# GD32A72_A74x register map
File version: 1.0
CPU: CM7 r2p1, little endian, MPU, FPU, DSP, 4 interrupt priority bits
Registers are 32-bit, read-write, reset 0x0 unless marked. A register's access mark holds for its fields unless they carry their own. Offsets are from the block's base; [hi:lo] are bit positions; {n}, {i} and the like mark numbered series; 'fields as' and 'values as' point back to an identical list.

## TRIGSEL — Trigger selection controller
Base 0x40012000
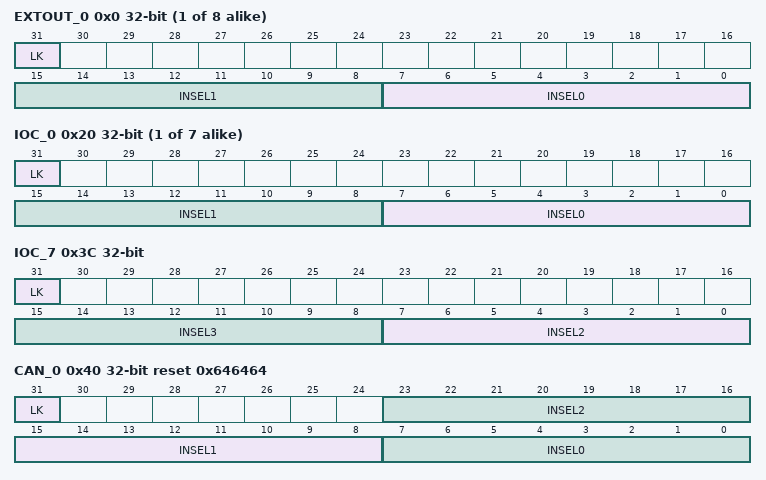
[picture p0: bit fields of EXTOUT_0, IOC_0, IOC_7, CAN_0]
{0x0+4i} EXTOUT_{i} (i=0..7) — Trigger selection for EXTOUT register {i}
  [31] LK — TRIGSEL register lock
  [15:8] INSEL1 — Trigger input source selection for output1
  [7:0] INSEL0 — Trigger input source selection for output0
{0x20+4i} IOC_{i} (i=0..6) — Trigger selection for IOC register {i}
  fields as EXTOUT_0
0x3C IOC_7 — Trigger selection for IOC register 7
  [31] LK — TRIGSEL register lock
  [15:8] INSEL3 — Trigger input source selection for output1
  [7:0] INSEL2 — Trigger input source selection for output0
0x40 CAN_0 reset 0x646464 — Trigger selection for CAN register 0
  [31] LK — TRIGSEL register lock
  [23:16] INSEL2 — Trigger input source selection for output2
  [15:8] INSEL1 — Trigger input source selection for output1
  [7:0] INSEL0 — Trigger input source selection for output0
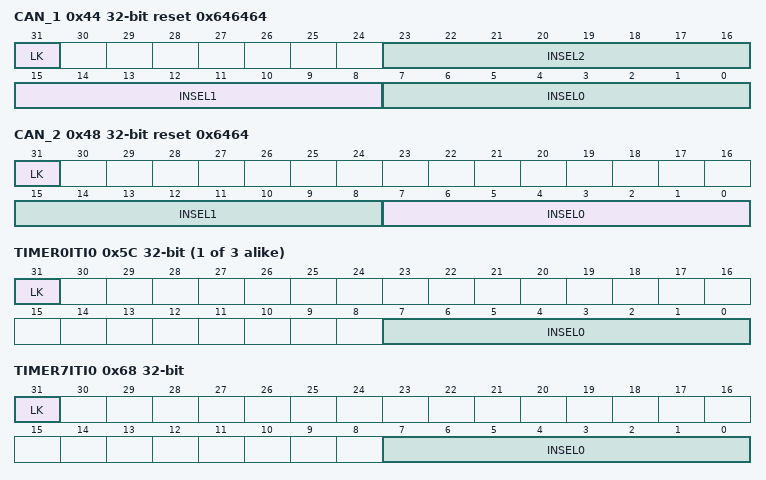
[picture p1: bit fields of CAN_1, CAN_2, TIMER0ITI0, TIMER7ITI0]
0x44 CAN_1 reset 0x646464 — Trigger selection for CAN register 1
  fields as CAN_0
0x48 CAN_2 reset 0x6464 — Trigger selection for CAN register 2
  fields as EXTOUT_0
{0x5C+4i} TIMER{i}ITI0 (i=0..2) — Trigger selection for TIMER{i}_ITI0 register
  [31] LK — TRIGSEL register lock
  [7:0] INSEL0 — Trigger input source selection for output0
0x68 TIMER7ITI0 — Trigger selection for TIMER7_ITI0 register
  fields as TIMER0ITI0
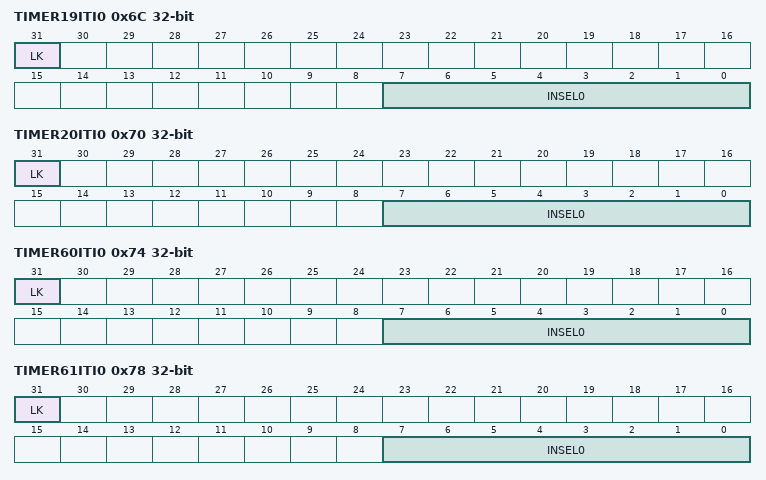
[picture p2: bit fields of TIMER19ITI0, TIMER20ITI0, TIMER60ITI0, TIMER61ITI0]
0x6C TIMER19ITI0 — Trigger selection for TIMER19_ITI0 register
  fields as TIMER0ITI0
0x70 TIMER20ITI0 — Trigger selection for TIMER20_ITI0 register
  fields as TIMER0ITI0
0x74 TIMER60ITI0 — Trigger selection for TIMER60_ITI0 register
  fields as TIMER0ITI0
0x78 TIMER61ITI0 — Trigger selection for TIMER61_ITI0 register
  fields as TIMER0ITI0
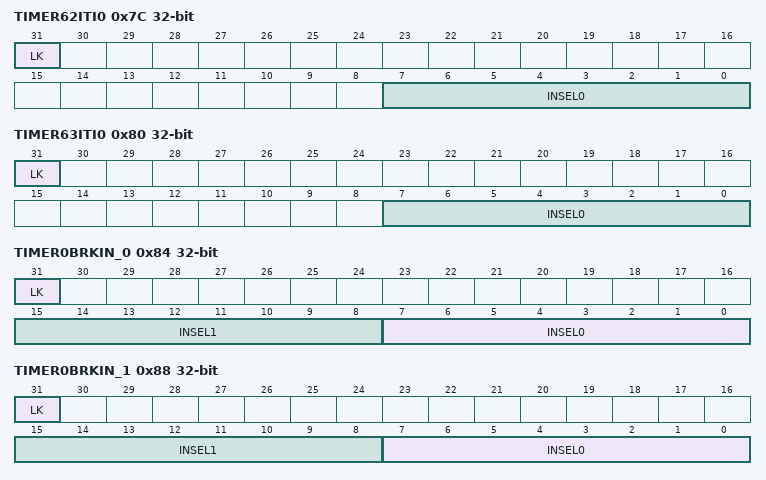
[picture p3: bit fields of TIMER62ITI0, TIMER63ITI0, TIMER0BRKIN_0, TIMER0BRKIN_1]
0x7C TIMER62ITI0 — Trigger selection for TIMER62_ITI0 register
  fields as TIMER0ITI0
0x80 TIMER63ITI0 — Trigger selection for TIMER63_ITI0 register
  fields as TIMER0ITI0
0x84 TIMER0BRKIN_0 — Trigger selection for TIMER0_BRKIN register 0
  fields as EXTOUT_0
0x88 TIMER0BRKIN_1 — Trigger selection for TIMER0_BRKIN register 1
  fields as EXTOUT_0
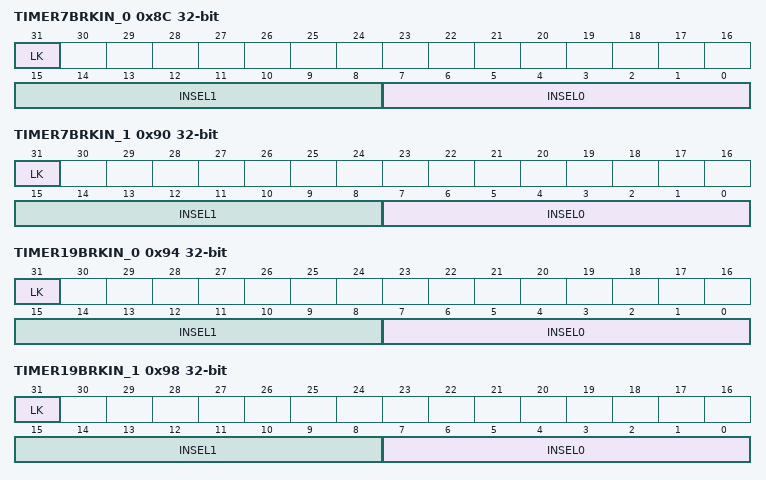
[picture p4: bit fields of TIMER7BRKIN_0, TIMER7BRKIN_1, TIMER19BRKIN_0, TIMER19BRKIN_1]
0x8C TIMER7BRKIN_0 — Trigger selection for TIMER7_BRKIN register 0
  fields as EXTOUT_0
0x90 TIMER7BRKIN_1 — Trigger selection for TIMER7_BRKIN register 1
  fields as EXTOUT_0
0x94 TIMER19BRKIN_0 — Trigger selection for TIMER19_BRKIN register 0
  fields as EXTOUT_0
0x98 TIMER19BRKIN_1 — Trigger selection for TIMER19_BRKIN register 1
  fields as EXTOUT_0
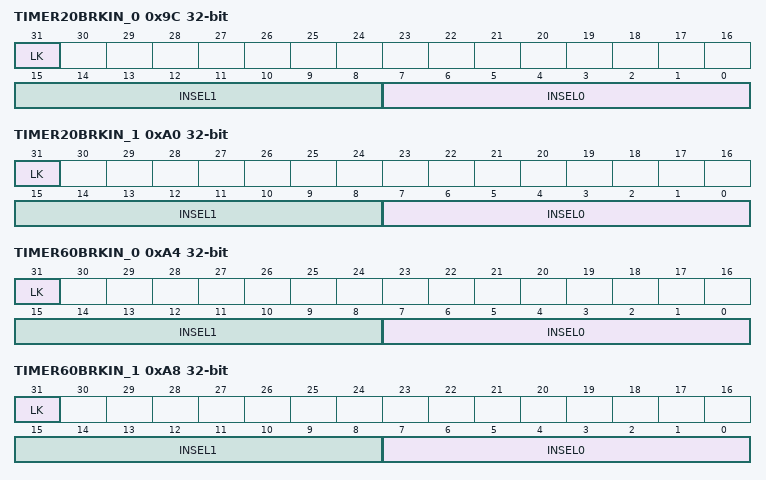
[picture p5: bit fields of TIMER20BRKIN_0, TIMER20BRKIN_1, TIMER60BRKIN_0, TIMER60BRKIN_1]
0x9C TIMER20BRKIN_0 — Trigger selection for TIMER20_BRKIN register 0
  fields as EXTOUT_0
0xA0 TIMER20BRKIN_1 — Trigger selection for TIMER20_BRKIN register 1
  fields as EXTOUT_0
0xA4 TIMER60BRKIN_0 — Trigger selection for TIMER60_BRKIN register 0
  fields as EXTOUT_0
0xA8 TIMER60BRKIN_1 — Trigger selection for TIMER60_BRKIN register 1
  fields as EXTOUT_0
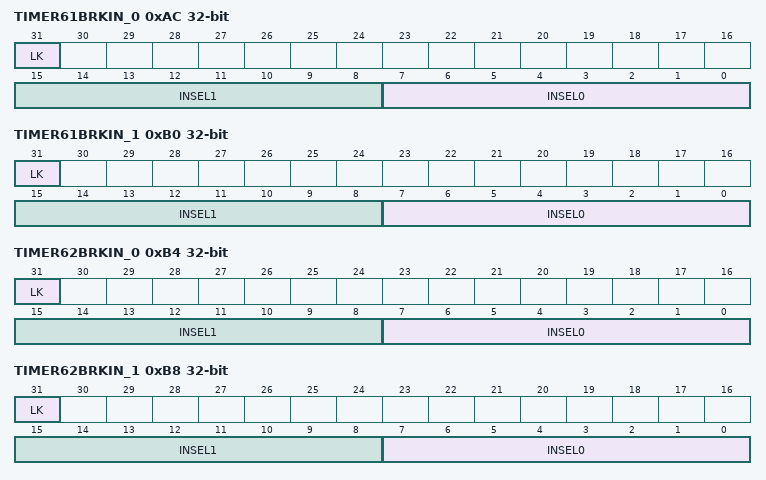
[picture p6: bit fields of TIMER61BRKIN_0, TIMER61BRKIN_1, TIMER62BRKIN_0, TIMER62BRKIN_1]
0xAC TIMER61BRKIN_0 — Trigger selection for TIMER61_BRKIN register 0
  fields as EXTOUT_0
0xB0 TIMER61BRKIN_1 — Trigger selection for TIMER61_BRKIN register 1
  fields as EXTOUT_0
0xB4 TIMER62BRKIN_0 — Trigger selection for TIMER62_BRKIN register 0
  fields as EXTOUT_0
0xB8 TIMER62BRKIN_1 — Trigger selection for TIMER62_BRKIN register 1
  fields as EXTOUT_0
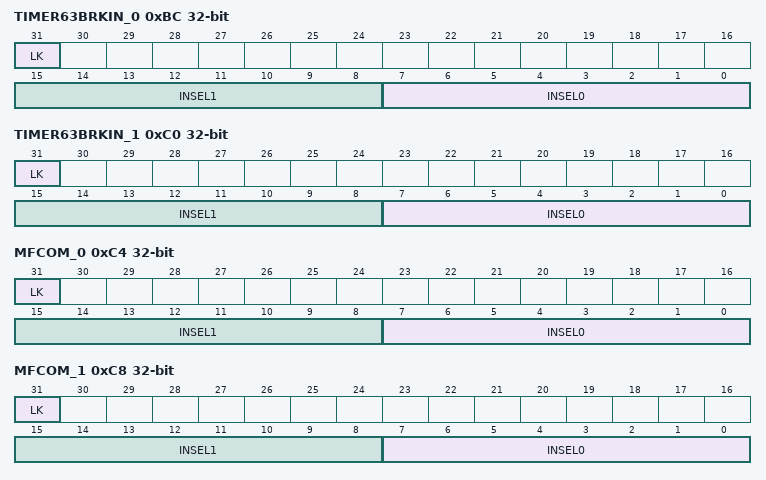
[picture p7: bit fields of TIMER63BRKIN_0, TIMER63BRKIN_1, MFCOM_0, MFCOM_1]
0xBC TIMER63BRKIN_0 — Trigger selection for TIMER63_BRKIN register 0
  fields as EXTOUT_0
0xC0 TIMER63BRKIN_1 — Trigger selection for TIMER63_BRKIN register 1
  fields as EXTOUT_0
0xC4 MFCOM_0 — Trigger selection for MFCOM register 0
  fields as EXTOUT_0
0xC8 MFCOM_1 — Trigger selection for MFCOM register 1
  fields as EXTOUT_0
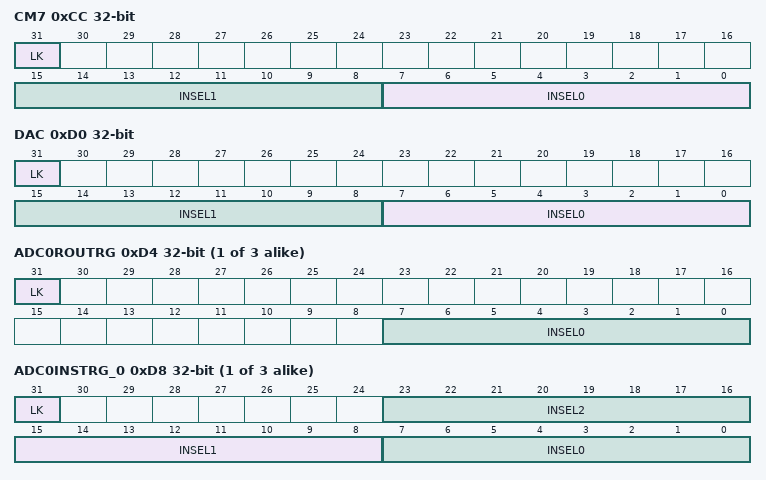
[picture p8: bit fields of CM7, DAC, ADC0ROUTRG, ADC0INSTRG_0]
0xCC CM7 — Trigger selection for CM7 register
  fields as EXTOUT_0
0xD0 DAC — Trigger selection for DAC register
  fields as EXTOUT_0
{0xD4+0xC*i} ADC{i}ROUTRG (i=0..2) — Trigger selection for ADC{i}_ROUTRG register
  fields as TIMER0ITI0
{0xD8+0xC*i} ADC{i}INSTRG_0 (i=0..2) — Trigger selection for ADC{i}_INSTRG register 0
  fields as CAN_0
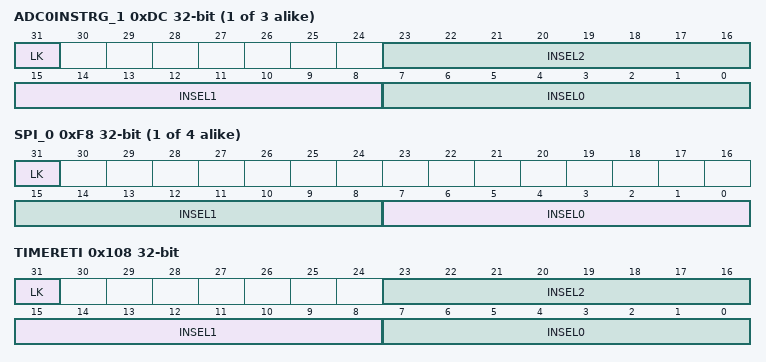
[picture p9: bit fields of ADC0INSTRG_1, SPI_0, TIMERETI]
{0xDC+0xC*i} ADC{i}INSTRG_1 (i=0..2) — Trigger selection for ADC{i}_INSTRG register 1
  fields as CAN_0
{0xF8+4i} SPI_{i} (i=0..3) — Trigger selection for SPI register {i}
  fields as EXTOUT_0
0x108 TIMERETI — Trigger selection for TIMER_ETI register
  fields as CAN_0
